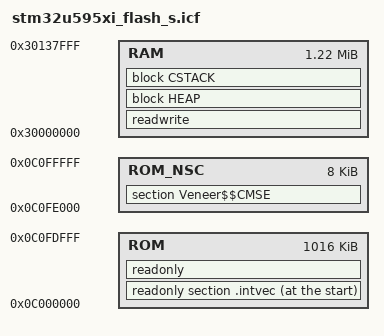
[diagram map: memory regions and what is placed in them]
/**
******************************************************************************
* @file    stm32u595xi_flash_s.icf
* @brief   Linker File
******************************************************************************
* @attention
*
* Copyright (c) 2022-2025 STMicroelectronics.
* All rights reserved.
*
* This software is licensed under terms that can be found in the LICENSE file
* in the root directory of this software component.
* If no LICENSE file comes with this software, it is provided AS-IS.
*
******************************************************************************
*/

define memory mem with size = 4G;
define region ROM = mem:[from 0xC000000 size 0xFE000];
define region ROM_NSC = mem:[from 0xC0FE000 size 0x2000];
define region RAM = mem:[from 0x30000000 size 0x138000];

/* define blocks */
define block HEAP with alignment = 8, size = 0x200 { };
define block CSTACK with alignment = 8, size = 0x400 { };

/* setup initialization strategies */
initialize by copy {
  readwrite
};

do not initialize {
  section .noinit
};

place at start of ROM { readonly section .intvec } ;

/* sections placements */
place in ROM {
  readonly
};

place in RAM {
  readwrite,
  block HEAP,
  block CSTACK
};

place in ROM_NSC {
  section Veneer$$CMSE
};

